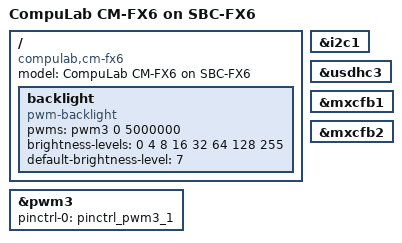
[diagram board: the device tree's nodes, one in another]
/*
* Copyright 2014 CompuLab Ltd.
*
* Author: Valentin Raevsky <valentin@compulab.co.il>
*
* The code contained herein is licensed under the GNU General Public
* License. You may obtain a copy of the GNU General Public License
* Version 2 or later at the following locations:
*
* http://www.opensource.org/licenses/gpl-license.html
* http://www.gnu.org/copyleft/gpl.html
*/

/dts-v1/;
#include "imx6q-sb-fx6.dtsi"
#include "imx6q-cm-fx6.dtsi"

/ {
   model = "CompuLab CM-FX6 on SBC-FX6";
   compatible = "compulab,cm-fx6", "compulab,sbc-fx6", "fsl,imx6q";

	backlight {
		compatible = "pwm-backlight";
		pwms = <&pwm3 0 5000000>;
		brightness-levels = <0 4 8 16 32 64 128 255>;
		default-brightness-level = <7>;
	};

};

&i2c1 {
	status = "okay";
};

&usdhc3 {
	status = "okay";
};

&pwm3 {
	pinctrl-names = "default";
	pinctrl-0 = <&pinctrl_pwm3_1>;
	status = "okay";
};

&mxcfb1 {
	status = "okay";
};

&mxcfb2 {
	status = "okay";
};
